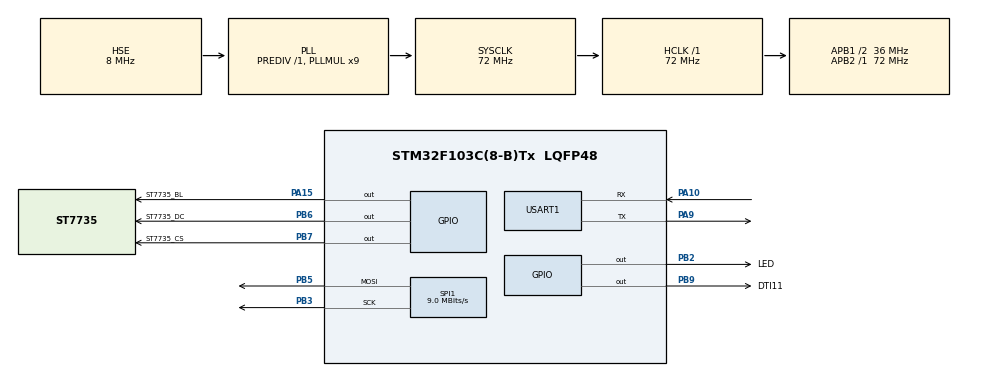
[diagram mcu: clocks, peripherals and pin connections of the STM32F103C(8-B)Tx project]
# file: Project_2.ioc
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ADC1.Channel-0\#ChannelRegularConversion=ADC_CHANNEL_TEMPSENSOR
ADC1.NbrOfConversionFlag=1
ADC1.Rank-0\#ChannelRegularConversion=1
ADC1.SamplingTime-0\#ChannelRegularConversion=ADC_SAMPLETIME_239CYCLES_5
ADC1.master=1
Dma.Request0=USART1_RX
Dma.Request1=USART1_TX
Dma.USART1_RX.0.Direction=DMA_PERIPH_TO_MEMORY
Dma.USART1_RX.0.Instance=DMA1_Channel5
Dma.USART1_RX.0.MemDataAlignment=DMA_MDATAALIGN_BYTE
Dma.USART1_RX.0.MemInc=DMA_MINC_ENABLE
Dma.USART1_RX.0.Mode=DMA_NORMAL
Dma.USART1_RX.0.PeriphDataAlignment=DMA_PDATAALIGN_BYTE
Dma.USART1_RX.0.PeriphInc=DMA_PINC_DISABLE
Dma.USART1_RX.0.Priority=DMA_PRIORITY_LOW
Dma.USART1_TX.1.Direction=DMA_MEMORY_TO_PERIPH
Dma.USART1_TX.1.Instance=DMA1_Channel4
Dma.USART1_TX.1.MemDataAlignment=DMA_MDATAALIGN_BYTE
Dma.USART1_TX.1.MemInc=DMA_MINC_ENABLE
Dma.USART1_TX.1.Mode=DMA_NORMAL
Dma.USART1_TX.1.PeriphDataAlignment=DMA_PDATAALIGN_BYTE
Dma.USART1_TX.1.PeriphInc=DMA_PINC_DISABLE
Dma.USART1_TX.1.Priority=DMA_PRIORITY_LOW
IWDG.Prescaler=IWDG_PRESCALER_16
IWDG.Reload=2046
Mcu.Family=STM32F1
Mcu.Name=STM32F103C(8-B)Tx
Mcu.Package=LQFP48
NVIC.DMA1_Channel4_IRQn=true\:0\:0\:false\:false\:true\:false\:true\:true
NVIC.DMA1_Channel5_IRQn=true\:0\:0\:false\:false\:true\:false\:true\:true
NVIC.PriorityGroup=NVIC_PRIORITYGROUP_4
NVIC.TIM4_IRQn=true\:0\:0\:false\:false\:true\:true\:true\:true
NVIC.USART1_IRQn=true\:0\:0\:false\:false\:true\:true\:true\:true
PA10.Mode=Asynchronous
PA10.Signal=USART1_RX
PA13.Mode=Serial_Wire
PA13.Signal=SYS_JTMS-SWDIO
PA14.Mode=Serial_Wire
PA14.Signal=SYS_JTCK-SWCLK
PA15.GPIO_Label=ST7735_BL
PA15.GPIO_Speed=GPIO_SPEED_FREQ_HIGH
PA15.Signal=GPIO_Output
PA9.Mode=Asynchronous
PA9.Signal=USART1_TX
PB2.GPIO_Label=LED
PB2.GPIO_PuPd=GPIO_PULLUP
PB2.GPIO_Speed=GPIO_SPEED_FREQ_HIGH
PB2.PinState=GPIO_PIN_SET
PB2.Signal=GPIO_Output
PB3.Mode=TX_Only_Simplex_Unidirect_Master
PB3.Signal=SPI1_SCK
PB5.Mode=TX_Only_Simplex_Unidirect_Master
PB5.Signal=SPI1_MOSI
PB6.GPIO_Label=ST7735_DC
PB6.GPIO_Speed=GPIO_SPEED_FREQ_HIGH
PB6.PinState=GPIO_PIN_SET
PB6.Signal=GPIO_Output
PB7.GPIO_Label=ST7735_CS
PB7.GPIO_Speed=GPIO_SPEED_FREQ_HIGH
PB7.PinState=GPIO_PIN_SET
PB7.Signal=GPIO_Output
PB9.GPIO_Label=DTI11
PB9.Signal=GPIO_Output
PC14-OSC32_IN.Mode=LSE-External-Oscillator
PC14-OSC32_IN.Signal=RCC_OSC32_IN
PC15-OSC32_OUT.Mode=LSE-External-Oscillator
PC15-OSC32_OUT.Signal=RCC_OSC32_OUT
PD0-OSC_IN.Mode=HSE-External-Oscillator
PD0-OSC_IN.Signal=RCC_OSC_IN
PD1-OSC_OUT.Mode=HSE-External-Oscillator
PD1-OSC_OUT.Signal=RCC_OSC_OUT
ProjectManager.HeapSize=0x200
ProjectManager.StackSize=0x400
ProjectManager.TargetToolchain=STM32CubeIDE
RCC.ADCPresc=RCC_ADCPCLK2_DIV6
RCC.AHBFreq_Value=72000000
RCC.APB1CLKDivider=RCC_HCLK_DIV2
RCC.APB1Freq_Value=36000000
RCC.APB1TimFreq_Value=72000000
RCC.APB2Freq_Value=72000000
RCC.APB2TimFreq_Value=72000000
RCC.HCLKFreq_Value=72000000
RCC.PLLMUL=RCC_PLL_MUL9
RCC.PLLSourceVirtual=RCC_PLLSOURCE_HSE
RCC.RTCClockSelection=RCC_RTCCLKSOURCE_LSE
RCC.SYSCLKFreq_VALUE=72000000
RCC.SYSCLKSource=RCC_SYSCLKSOURCE_PLLCLK
RCC.USBFreq_Value=72000000
SPI1.BaudRatePrescaler=SPI_BAUDRATEPRESCALER_8
SPI1.CalculateBaudRate=9.0 MBits/s
SPI1.Direction=SPI_DIRECTION_2LINES
SPI1.Mode=SPI_MODE_MASTER
SPI1.VirtualType=VM_MASTER
TIM4.Period=124
TIM4.Prescaler=71
USART1.VirtualMode=VM_ASYNC
VP_ADC1_TempSens_Input.Mode=IN-TempSens
VP_IWDG_VS_IWDG.Mode=IWDG_Activate
VP_TIM4_VS_ClockSourceINT.Mode=Internal
board=custom

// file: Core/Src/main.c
/* USER CODE BEGIN Header */
/**
  ******************************************************************************
  * @file           : main.c
  * @brief          : Main program body
  ******************************************************************************
  * @attention
  *
  * Copyright (c) 2025 STMicroelectronics.
  * All rights reserved.
  *
  * This software is licensed under terms that can be found in the LICENSE file
  * in the root directory of this software component.
  * If no LICENSE file comes with this software, it is provided AS-IS.
  *
  ******************************************************************************
  */
/* USER CODE END Header */
#include "main.h"
#include "adc.h"
#include "dma.h"
#include "iwdg.h"
#include "spi.h"
#include "tim.h"
#include "usart.h"
#include "gpio.h"

/* USER CODE BEGIN Includes */
#include "st7735.h"
/* USER CODE END Includes */

/* USER CODE BEGIN PTD */
CNT Cnt;
hc_sr04 HC_SR04;
/* USER CODE END PTD */

/* USER CODE BEGIN PV */
volatile bits	StateF;
volatile bits	OtherF;

uint8_t Rarr[5] = {0};
/* USER CODE END PV */

void SystemClock_Config(void);

int main(void)
{

  /* MCU Configuration--------------------------------------------------------*/

  /* Reset of all peripherals, Initializes the Flash interface and the Systick. */
  HAL_Init();

  /* Configure the system clock */
  SystemClock_Config();

  /* Initialize all configured peripherals */
  MX_GPIO_Init();
  MX_DMA_Init();
  MX_USART1_UART_Init();
  MX_TIM4_Init();
  MX_IWDG_Init();
  MX_SPI1_Init();
  MX_ADC1_Init();
  /* USER CODE BEGIN 2 */
  User_Init();
  ST7735_Init();
  HAL_UART_Receive_DMA(&huart1, Rarr, 5);
  /* USER CODE END 2 */

  /* Infinite loop */
  /* USER CODE BEGIN WHILE */
  while (1)
  {
	  Task_20ms_DIV();
	  //Serial_SendArray(Tarr, sizeof(Tarr)/sizeof(Tarr[0]));
	  //HAL_Delay(1000);

//	  ST7735_FillScreen(ST7735_RED);
//	  HAL_Delay(500);
//	  ST7735_FillScreen(ST7735_GREEN);
//	  HAL_Delay(500);
//	  ST7735_FillScreen(ST7735_BLUE);
//	  HAL_Delay(500);

//	  float temp;
//	  temp = Get_Temprate();

//	  ST7735_DrawString(0, 0, "CSDN666", ST7735_BLUE, ST7735_BLACK, &Font_11x18);

	  //Serial_SendString(temp);
//	  printf("temp: %.2f\n", temp);
//	  HAL_Delay(500);

    /* USER CODE END WHILE */

  }
}

void SystemClock_Config(void)
{
  RCC_OscInitTypeDef RCC_OscInitStruct = {0};
  RCC_ClkInitTypeDef RCC_ClkInitStruct = {0};
  RCC_PeriphCLKInitTypeDef PeriphClkInit = {0};

  /** Initializes the RCC Oscillators according to the specified parameters
  * in the RCC_OscInitTypeDef structure.
  */
  RCC_OscInitStruct.OscillatorType = RCC_OSCILLATORTYPE_LSI|RCC_OSCILLATORTYPE_HSE;
  RCC_OscInitStruct.HSEState = RCC_HSE_ON;
  RCC_OscInitStruct.HSEPredivValue = RCC_HSE_PREDIV_DIV1;
  RCC_OscInitStruct.HSIState = RCC_HSI_ON;
  RCC_OscInitStruct.LSIState = RCC_LSI_ON;
  RCC_OscInitStruct.PLL.PLLState = RCC_PLL_ON;
  RCC_OscInitStruct.PLL.PLLSource = RCC_PLLSOURCE_HSE;
  RCC_OscInitStruct.PLL.PLLMUL = RCC_PLL_MUL9;
  if (HAL_RCC_OscConfig(&RCC_OscInitStruct) != HAL_OK)
  {
    Error_Handler();
  }

  /** Initializes the CPU, AHB and APB buses clocks
  */
  RCC_ClkInitStruct.ClockType = RCC_CLOCKTYPE_HCLK|RCC_CLOCKTYPE_SYSCLK
                              |RCC_CLOCKTYPE_PCLK1|RCC_CLOCKTYPE_PCLK2;
  RCC_ClkInitStruct.SYSCLKSource = RCC_SYSCLKSOURCE_PLLCLK;
  RCC_ClkInitStruct.AHBCLKDivider = RCC_SYSCLK_DIV1;
  RCC_ClkInitStruct.APB1CLKDivider = RCC_HCLK_DIV2;
  RCC_ClkInitStruct.APB2CLKDivider = RCC_HCLK_DIV1;

  if (HAL_RCC_ClockConfig(&RCC_ClkInitStruct, FLASH_LATENCY_2) != HAL_OK)
  {
    Error_Handler();
  }
  PeriphClkInit.PeriphClockSelection = RCC_PERIPHCLK_ADC;
  PeriphClkInit.AdcClockSelection = RCC_ADCPCLK2_DIV6;
  if (HAL_RCCEx_PeriphCLKConfig(&PeriphClkInit) != HAL_OK)
  {
    Error_Handler();
  }
}

void Error_Handler(void)
{
  __disable_irq();
  while (1)
  {
  }
}
